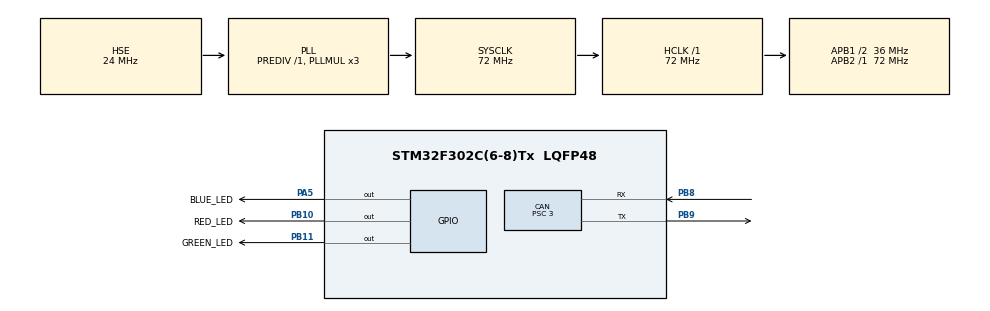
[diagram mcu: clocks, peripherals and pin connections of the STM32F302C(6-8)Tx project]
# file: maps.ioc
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CAN.BS1=CAN_BS1_7TQ
CAN.BS2=CAN_BS2_4TQ
CAN.CalculateBaudRate=999999
CAN.CalculateTimeBit=1000
CAN.CalculateTimeQuantum=83.33333333333334
CAN.Prescaler=3
Mcu.Family=STM32F3
Mcu.Name=STM32F302C(6-8)Tx
Mcu.Package=LQFP48
NVIC.CAN_RX1_IRQn=true\:0\:0\:false\:false\:true\:true\:true\:true
NVIC.PriorityGroup=NVIC_PRIORITYGROUP_4
PA5.GPIO_Label=BLUE_LED
PA5.Signal=GPIO_Output
PB10.GPIO_Label=RED_LED
PB10.Signal=GPIO_Output
PB11.GPIO_Label=GREEN_LED
PB11.Signal=GPIO_Output
PB8.Mode=CAN_Activate
PB8.Signal=CAN_RX
PB9.Mode=CAN_Activate
PB9.Signal=CAN_TX
PF0-OSC_IN.Mode=HSE-External-Clock-Source
PF0-OSC_IN.Signal=RCC_OSC_IN
ProjectManager.HeapSize=0x200
ProjectManager.StackSize=0x400
ProjectManager.TargetToolchain=STM32CubeIDE
RCC.AHBFreq_Value=72000000
RCC.APB1CLKDivider=RCC_HCLK_DIV2
RCC.APB1Freq_Value=36000000
RCC.APB1TimFreq_Value=72000000
RCC.APB2Freq_Value=72000000
RCC.APB2TimFreq_Value=72000000
RCC.CortexFreq_Value=72000000
RCC.HCLKFreq_Value=72000000
RCC.HSE_VALUE=24000000
RCC.HSI_VALUE=8000000
RCC.LSE_VALUE=32768
RCC.PLLMUL=RCC_PLL_MUL3
RCC.PLLSourceVirtual=RCC_PLLSOURCE_HSE
RCC.SYSCLKFreq_VALUE=72000000
RCC.SYSCLKSourceVirtual=RCC_SYSCLKSOURCE_PLLCLK
RCC.USBFreq_Value=72000000
board=custom

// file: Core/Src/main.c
/* USER CODE BEGIN Header */
/**
  ******************************************************************************
  * @file           : main.c
  * @brief          : Main program body
  ******************************************************************************
  * @attention
  *
  * Copyright (c) 2026 STMicroelectronics.
  * All rights reserved.
  *
  * This software is licensed under terms that can be found in the LICENSE file
  * in the root directory of this software component.
  * If no LICENSE file comes with this software, it is provided AS-IS.
  *
  ******************************************************************************
  */
/* USER CODE END Header */
#include "main.h"

/* USER CODE BEGIN Includes */

#include "can_handler.h"

/* USER CODE END Includes */

CAN_HandleTypeDef hcan;

void SystemClock_Config(void);
static void MX_GPIO_Init(void);
static void MX_CAN_Init(void);

int main(void)
{

  /* MCU Configuration--------------------------------------------------------*/

  /* Reset of all peripherals, Initializes the Flash interface and the Systick. */
  HAL_Init();

  /* Configure the system clock */
  SystemClock_Config();

  /* Initialize all configured peripherals */
  MX_GPIO_Init();
  MX_CAN_Init();
  /* USER CODE BEGIN 2 */

  if(HAL_CAN_Start(&hcan) != HAL_OK) Error_Handler();
  HAL_CAN_ActivateNotification(&hcan, CAN_IT_RX_FIFO1_MSG_PENDING);

  /* USER CODE END 2 */

  /* Infinite loop */
  while (1)
  {

  }
}

void SystemClock_Config(void)
{
  RCC_OscInitTypeDef RCC_OscInitStruct = {0};
  RCC_ClkInitTypeDef RCC_ClkInitStruct = {0};

  /** Initializes the RCC Oscillators according to the specified parameters
  * in the RCC_OscInitTypeDef structure.
  */
  RCC_OscInitStruct.OscillatorType = RCC_OSCILLATORTYPE_HSE;
  RCC_OscInitStruct.HSEState = RCC_HSE_BYPASS;
  RCC_OscInitStruct.HSEPredivValue = RCC_HSE_PREDIV_DIV1;
  RCC_OscInitStruct.HSIState = RCC_HSI_ON;
  RCC_OscInitStruct.PLL.PLLState = RCC_PLL_ON;
  RCC_OscInitStruct.PLL.PLLSource = RCC_PLLSOURCE_HSE;
  RCC_OscInitStruct.PLL.PLLMUL = RCC_PLL_MUL3;
  if (HAL_RCC_OscConfig(&RCC_OscInitStruct) != HAL_OK)
  {
    Error_Handler();
  }

  /** Initializes the CPU, AHB and APB buses clocks
  */
  RCC_ClkInitStruct.ClockType = RCC_CLOCKTYPE_HCLK|RCC_CLOCKTYPE_SYSCLK
                              |RCC_CLOCKTYPE_PCLK1|RCC_CLOCKTYPE_PCLK2;
  RCC_ClkInitStruct.SYSCLKSource = RCC_SYSCLKSOURCE_PLLCLK;
  RCC_ClkInitStruct.AHBCLKDivider = RCC_SYSCLK_DIV1;
  RCC_ClkInitStruct.APB1CLKDivider = RCC_HCLK_DIV2;
  RCC_ClkInitStruct.APB2CLKDivider = RCC_HCLK_DIV1;

  if (HAL_RCC_ClockConfig(&RCC_ClkInitStruct, FLASH_LATENCY_2) != HAL_OK)
  {
    Error_Handler();
  }
}

static void MX_CAN_Init(void)
{

  hcan.Instance = CAN;
  hcan.Init.Prescaler = 3;
  hcan.Init.Mode = CAN_MODE_NORMAL;
  hcan.Init.SyncJumpWidth = CAN_SJW_1TQ;
  hcan.Init.TimeSeg1 = CAN_BS1_7TQ;
  hcan.Init.TimeSeg2 = CAN_BS2_4TQ;
  hcan.Init.TimeTriggeredMode = DISABLE;
  hcan.Init.AutoBusOff = DISABLE;
  hcan.Init.AutoWakeUp = DISABLE;
  hcan.Init.AutoRetransmission = DISABLE;
  hcan.Init.ReceiveFifoLocked = DISABLE;
  hcan.Init.TransmitFifoPriority = DISABLE;
  if (HAL_CAN_Init(&hcan) != HAL_OK)
  {
    Error_Handler();
  }
  /* USER CODE BEGIN CAN_Init 2 */

  CAN_CONFIG(&hcan);

  /* USER CODE END CAN_Init 2 */

}

static void MX_GPIO_Init(void)
{
  GPIO_InitTypeDef GPIO_InitStruct = {0};

  /* GPIO Ports Clock Enable */
  __HAL_RCC_GPIOF_CLK_ENABLE();
  __HAL_RCC_GPIOA_CLK_ENABLE();
  __HAL_RCC_GPIOB_CLK_ENABLE();

  /*Configure GPIO pin Output Level */
  HAL_GPIO_WritePin(BLUE_LED_GPIO_Port, BLUE_LED_Pin, GPIO_PIN_RESET);

  /*Configure GPIO pin Output Level */
  HAL_GPIO_WritePin(GPIOB, RED_LED_Pin|GREEN_LED_Pin, GPIO_PIN_RESET);

  /*Configure GPIO pin : BLUE_LED_Pin */
  GPIO_InitStruct.Pin = BLUE_LED_Pin;
  GPIO_InitStruct.Mode = GPIO_MODE_OUTPUT_PP;
  GPIO_InitStruct.Pull = GPIO_NOPULL;
  GPIO_InitStruct.Speed = GPIO_SPEED_FREQ_LOW;
  HAL_GPIO_Init(BLUE_LED_GPIO_Port, &GPIO_InitStruct);

  /*Configure GPIO pins : RED_LED_Pin GREEN_LED_Pin */
  GPIO_InitStruct.Pin = RED_LED_Pin|GREEN_LED_Pin;
  GPIO_InitStruct.Mode = GPIO_MODE_OUTPUT_PP;
  GPIO_InitStruct.Pull = GPIO_NOPULL;
  GPIO_InitStruct.Speed = GPIO_SPEED_FREQ_LOW;
  HAL_GPIO_Init(GPIOB, &GPIO_InitStruct);

}

/* USER CODE BEGIN 4 */

	void HAL_CAN_RxFifo1MsgPendingCallback(CAN_HandleTypeDef *hcan) {
		CAN_RxHeaderTypeDef rxHeader;
		uint8_t rxData[8];

		if (HAL_CAN_GetRxMessage(hcan, CAN_RX_FIFO1, &rxHeader, rxData) == HAL_OK) {
			CAN_Process_Incoming(rxHeader.ExtId, rxData, rxHeader.DLC);
		}
	}

/* USER CODE END 4 */

void Error_Handler(void)
{
  __disable_irq();
  while (1)
  {
  }
}
